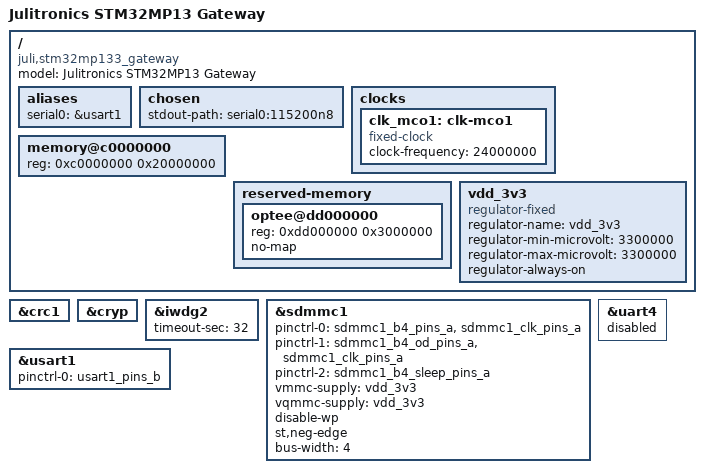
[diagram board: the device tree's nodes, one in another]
// SPDX-License-Identifier: (GPL-2.0+ OR BSD-3-Clause)
/*
 */

/dts-v1/;

#include <dt-bindings/gpio/gpio.h>
#include <dt-bindings/input/input.h>
#include <dt-bindings/leds/common.h>
#include <dt-bindings/regulator/st,stm32mp13-regulator.h>
#include "stm32mp135.dtsi"
#include "stm32mp13xf.dtsi"
#include "stm32mp13-pinctrl.dtsi"

/ {
	model = "Julitronics STM32MP13 Gateway";
	compatible = "juli,stm32mp133_gateway", "st,stm32mp135";

	aliases {
		serial0 = &usart1;
	};

	chosen {
		stdout-path = "serial0:115200n8";
	};

	clocks {
		clk_mco1: clk-mco1 {
			#clock-cells = <0>;
			compatible = "fixed-clock";
			clock-frequency = <24000000>;
		};
	};

	memory@c0000000 {
		device_type = "memory";
		reg = <0xc0000000 0x20000000>;
	};

	reserved-memory {
		#address-cells = <1>;
		#size-cells = <1>;
		ranges;

		optee@dd000000 {
			reg = <0xdd000000 0x3000000>;
			no-map;
		};
	};
	
	vdd_3v3: vdd_3v3 {
		compatible = "regulator-fixed";
		regulator-name = "vdd_3v3";
		regulator-min-microvolt = <3300000>;
		regulator-max-microvolt = <3300000>;
		regulator-always-on;
	};
};

&crc1 {
	status = "okay";
};

&cryp {
	status = "okay";
};

&iwdg2 {
	timeout-sec = <32>;
	status = "okay";
};

&sdmmc1 {
	pinctrl-names = "default", "opendrain", "sleep";
	pinctrl-0 = <&sdmmc1_b4_pins_a &sdmmc1_clk_pins_a>;
	pinctrl-1 = <&sdmmc1_b4_od_pins_a &sdmmc1_clk_pins_a>;
	pinctrl-2 = <&sdmmc1_b4_sleep_pins_a>;
	vmmc-supply = <&vdd_3v3>;
	vqmmc-supply = <&vdd_3v3>;
	disable-wp;
	st,neg-edge;
	bus-width = <4>;
	status = "okay";
};

&uart4 {
	/delete-property/dmas;
	/delete-property/dma-names;
	status = "disabled";
};

&usart1 {
	/delete-property/dmas;
	/delete-property/dma-names;
	pinctrl-names = "default";
	pinctrl-0 = <&usart1_pins_b>;
	status = "okay";
};
